# PIC32MX695F512L register map
Registers are 32-bit, access not given, reset 0x0 unless marked. A register's access mark holds for its fields unless they carry their own. Offsets are from the block's base; [hi:lo] are bit positions; 'fields as' and 'values as' point back to an identical list.

## DMAC4 — DMAC4 peripheral
Base 0xBF883360
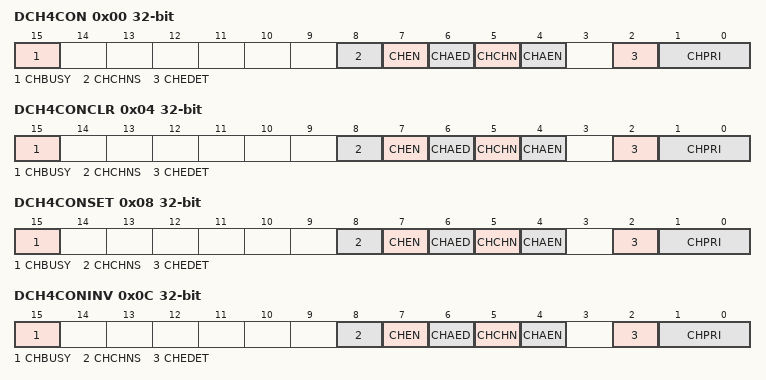
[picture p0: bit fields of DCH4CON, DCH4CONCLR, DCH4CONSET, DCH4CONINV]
0x00 DCH4CON
  [15] CHBUSY, [8] CHCHNS, [7] CHEN, [6] CHAED, [5] CHCHN, [4] CHAEN, [2] CHEDET, [1:0] CHPRI
0x04 DCH4CONCLR
  fields as DCH4CON
0x08 DCH4CONSET
  fields as DCH4CON
0x0C DCH4CONINV
  fields as DCH4CON
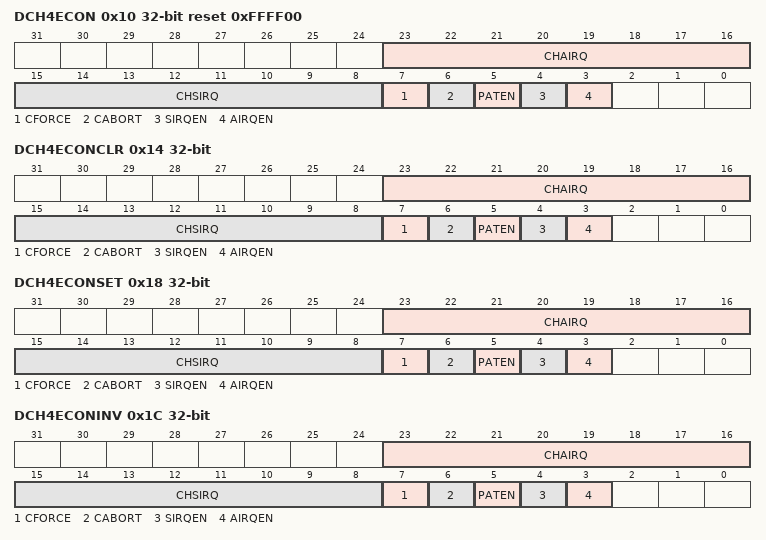
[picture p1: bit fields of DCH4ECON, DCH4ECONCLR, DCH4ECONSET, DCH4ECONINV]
0x10 DCH4ECON reset 0xFFFF00
  [23:16] CHAIRQ, [15:8] CHSIRQ, [7] CFORCE, [6] CABORT, [5] PATEN, [4] SIRQEN, [3] AIRQEN
0x14 DCH4ECONCLR
  fields as DCH4ECON
0x18 DCH4ECONSET
  fields as DCH4ECON
0x1C DCH4ECONINV
  fields as DCH4ECON
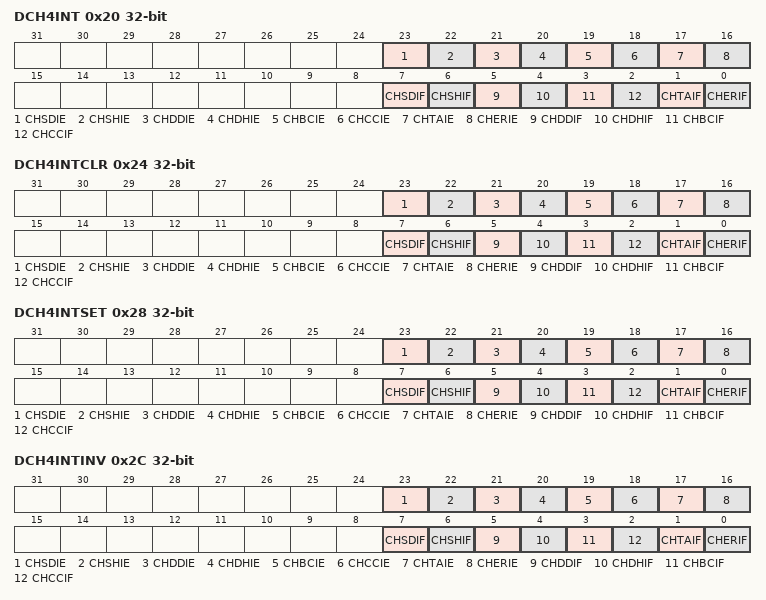
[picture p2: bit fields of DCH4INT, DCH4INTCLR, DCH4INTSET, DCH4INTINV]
0x20 DCH4INT
  [23] CHSDIE, [22] CHSHIE, [21] CHDDIE, [20] CHDHIE, [19] CHBCIE, [18] CHCCIE, [17] CHTAIE, [16] CHERIE, [7] CHSDIF, [6] CHSHIF, [5] CHDDIF, [4] CHDHIF, [3] CHBCIF, [2] CHCCIF, [1] CHTAIF, [0] CHERIF
0x24 DCH4INTCLR
  fields as DCH4INT
0x28 DCH4INTSET
  fields as DCH4INT
0x2C DCH4INTINV
  fields as DCH4INT
0x30 DCH4SSA
0x34 DCH4SSACLR
  [31:0] DCH4SSA
0x38 DCH4SSASET
  [31:0] DCH4SSA
0x3C DCH4SSAINV
  [31:0] DCH4SSA
0x40 DCH4DSA
0x44 DCH4DSACLR
  [31:0] DCH4DSA
0x48 DCH4DSASET
  [31:0] DCH4DSA
0x4C DCH4DSAINV
  [31:0] DCH4DSA
0x50 DCH4SSIZ
  [15:0] CHSSIZ
0x54 DCH4SSIZCLR
  [15:0] CHSSIZ
0x58 DCH4SSIZSET
  [15:0] CHSSIZ
0x5C DCH4SSIZINV
  [15:0] CHSSIZ
0x60 DCH4DSIZ
  [15:0] CHDSIZ
0x64 DCH4DSIZCLR
  [15:0] CHDSIZ
0x68 DCH4DSIZSET
  [15:0] CHDSIZ
0x6C DCH4DSIZINV
  [15:0] CHDSIZ
0x70 DCH4SPTR
  [15:0] CHSPTR
0x74 DCH4SPTRCLR
  [15:0] CHSPTR
0x78 DCH4SPTRSET
  [15:0] CHSPTR
0x7C DCH4SPTRINV
  [15:0] CHSPTR
0x80 DCH4DPTR
  [15:0] CHDPTR
0x84 DCH4DPTRCLR
  [15:0] CHDPTR
0x88 DCH4DPTRSET
  [15:0] CHDPTR
0x8C DCH4DPTRINV
  [15:0] CHDPTR
0x90 DCH4CSIZ
  [15:0] CHCSIZ
0x94 DCH4CSIZCLR
  [15:0] CHCSIZ
0x98 DCH4CSIZSET
  [15:0] CHCSIZ
0x9C DCH4CSIZINV
  [15:0] CHCSIZ
0xA0 DCH4CPTR
  [15:0] CHCPTR
0xA4 DCH4CPTRCLR
  [15:0] CHCPTR
0xA8 DCH4CPTRSET
  [15:0] CHCPTR
0xAC DCH4CPTRINV
  [15:0] CHCPTR
0xB0 DCH4DAT
  [7:0] DCHPDAT
0xB4 DCH4DATCLR
  [7:0] DCHPDAT
0xB8 DCH4DATSET
  [7:0] DCHPDAT
0xBC DCH4DATINV
  [7:0] DCHPDAT

## DMAC5 — DMAC5 peripheral
Base 0xBF883420
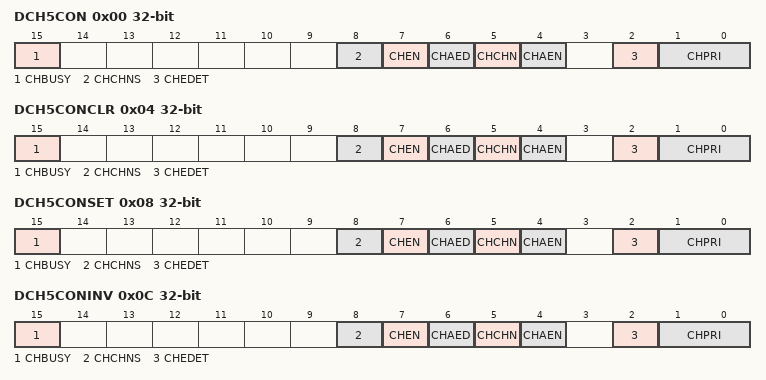
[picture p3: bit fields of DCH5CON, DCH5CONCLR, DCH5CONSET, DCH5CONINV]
0x00 DCH5CON
  [15] CHBUSY, [8] CHCHNS, [7] CHEN, [6] CHAED, [5] CHCHN, [4] CHAEN, [2] CHEDET, [1:0] CHPRI
0x04 DCH5CONCLR
  fields as DCH5CON
0x08 DCH5CONSET
  fields as DCH5CON
0x0C DCH5CONINV
  fields as DCH5CON
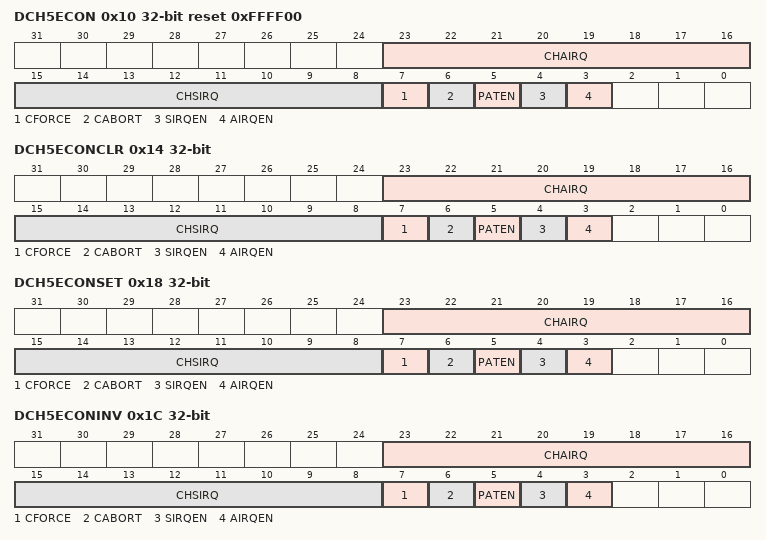
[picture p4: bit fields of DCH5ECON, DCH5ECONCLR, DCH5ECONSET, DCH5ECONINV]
0x10 DCH5ECON reset 0xFFFF00
  [23:16] CHAIRQ, [15:8] CHSIRQ, [7] CFORCE, [6] CABORT, [5] PATEN, [4] SIRQEN, [3] AIRQEN
0x14 DCH5ECONCLR
  fields as DCH5ECON
0x18 DCH5ECONSET
  fields as DCH5ECON
0x1C DCH5ECONINV
  fields as DCH5ECON
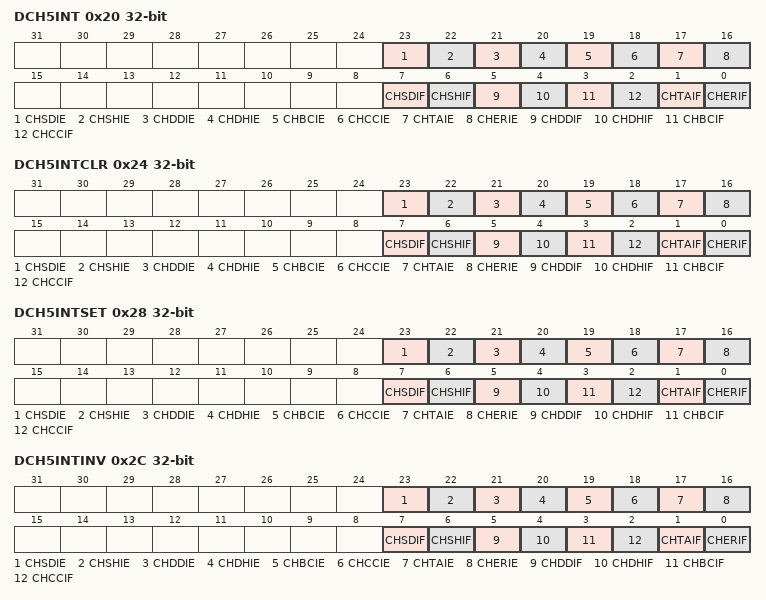
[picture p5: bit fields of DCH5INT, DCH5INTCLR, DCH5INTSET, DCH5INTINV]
0x20 DCH5INT
  [23] CHSDIE, [22] CHSHIE, [21] CHDDIE, [20] CHDHIE, [19] CHBCIE, [18] CHCCIE, [17] CHTAIE, [16] CHERIE, [7] CHSDIF, [6] CHSHIF, [5] CHDDIF, [4] CHDHIF, [3] CHBCIF, [2] CHCCIF, [1] CHTAIF, [0] CHERIF
0x24 DCH5INTCLR
  fields as DCH5INT
0x28 DCH5INTSET
  fields as DCH5INT
0x2C DCH5INTINV
  fields as DCH5INT
0x30 DCH5SSA
0x34 DCH5SSACLR
  [31:0] DCH5SSA
0x38 DCH5SSASET
  [31:0] DCH5SSA
0x3C DCH5SSAINV
  [31:0] DCH5SSA
0x40 DCH5DSA
0x44 DCH5DSACLR
  [31:0] DCH5DSA
0x48 DCH5DSASET
  [31:0] DCH5DSA
0x4C DCH5DSAINV
  [31:0] DCH5DSA
0x50 DCH5SSIZ
  [15:0] CHSSIZ
0x54 DCH5SSIZCLR
  [15:0] CHSSIZ
0x58 DCH5SSIZSET
  [15:0] CHSSIZ
0x5C DCH5SSIZINV
  [15:0] CHSSIZ
0x60 DCH5DSIZ
  [15:0] CHDSIZ
0x64 DCH5DSIZCLR
  [15:0] CHDSIZ
0x68 DCH5DSIZSET
  [15:0] CHDSIZ
0x6C DCH5DSIZINV
  [15:0] CHDSIZ
0x70 DCH5SPTR
  [15:0] CHSPTR
0x74 DCH5SPTRCLR
  [15:0] CHSPTR
0x78 DCH5SPTRSET
  [15:0] CHSPTR
0x7C DCH5SPTRINV
  [15:0] CHSPTR
0x80 DCH5DPTR
  [15:0] CHDPTR
0x84 DCH5DPTRCLR
  [15:0] CHDPTR
0x88 DCH5DPTRSET
  [15:0] CHDPTR
0x8C DCH5DPTRINV
  [15:0] CHDPTR
0x90 DCH5CSIZ
  [15:0] CHCSIZ
0x94 DCH5CSIZCLR
  [15:0] CHCSIZ
0x98 DCH5CSIZSET
  [15:0] CHCSIZ
0x9C DCH5CSIZINV
  [15:0] CHCSIZ
0xA0 DCH5CPTR
  [15:0] CHCPTR
0xA4 DCH5CPTRCLR
  [15:0] CHCPTR
0xA8 DCH5CPTRSET
  [15:0] CHCPTR
0xAC DCH5CPTRINV
  [15:0] CHCPTR
0xB0 DCH5DAT
  [7:0] DCHPDAT
0xB4 DCH5DATCLR
  [7:0] DCHPDAT
0xB8 DCH5DATSET
  [7:0] DCHPDAT
0xBC DCH5DATINV
  [7:0] DCHPDAT
